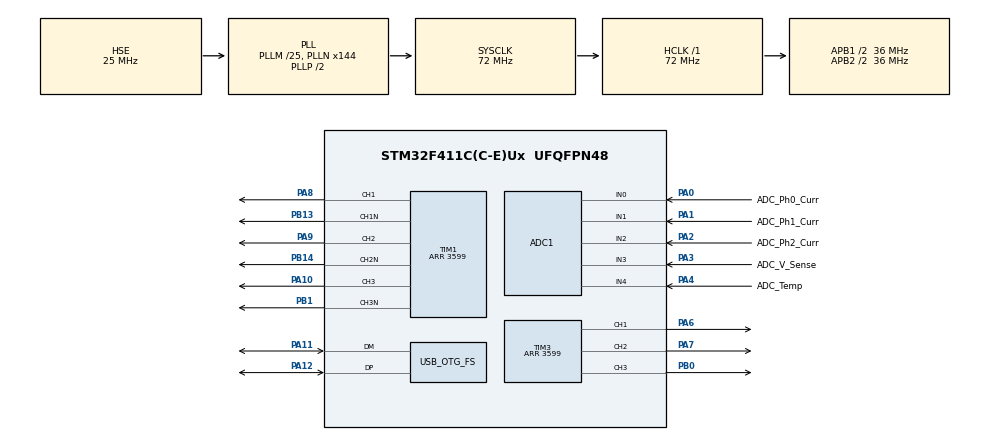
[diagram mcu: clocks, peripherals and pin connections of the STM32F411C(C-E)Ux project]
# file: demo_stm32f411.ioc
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ADC1.Channel-0\#ChannelRegularConversion=ADC_CHANNEL_0
ADC1.NbrOfConversionFlag=1
ADC1.Rank-0\#ChannelRegularConversion=1
ADC1.SamplingTime-0\#ChannelRegularConversion=ADC_SAMPLETIME_3CYCLES
ADC1.master=1
FREERTOS.Queues01=usbQueue,16,uint16_t,0,Dynamic,NULL,NULL
FREERTOS.Tasks01=defaultTask,24,1024,StartDefaultTask,Default,NULL,Dynamic,NULL,NULL;telemTask,8,1024,TelemThread,As external,NULL,Dynamic,NULL,NULL;usbTask,8,1024,UsbThread,As external,NULL,Dynamic,NULL,NULL
Mcu.Family=STM32F4
Mcu.Name=STM32F411C(C-E)Ux
Mcu.Package=UFQFPN48
NVIC.OTG_FS_IRQn=true\:5\:0\:false\:false\:true\:true\:false\:true\:true
NVIC.PriorityGroup=NVIC_PRIORITYGROUP_4
NVIC.TIM5_IRQn=true\:15\:0\:false\:false\:true\:false\:false\:true\:true
NVIC.TimeBase=TIM5_IRQn
NVIC.TimeBaseIP=TIM5
PA0-WKUP.GPIO_Label=ADC_Ph0_Curr
PA0-WKUP.Signal=ADCx_IN0
PA1.GPIO_Label=ADC_Ph1_Curr
PA1.Signal=ADCx_IN1
PA10.Signal=S_TIM1_CH3
PA11.Mode=Device_Only
PA11.Signal=USB_OTG_FS_DM
PA12.Mode=Device_Only
PA12.Signal=USB_OTG_FS_DP
PA13.Mode=Serial_Wire
PA13.Signal=SYS_JTMS-SWDIO
PA14.Mode=Serial_Wire
PA14.Signal=SYS_JTCK-SWCLK
PA2.GPIO_Label=ADC_Ph2_Curr
PA2.Signal=ADCx_IN2
PA3.GPIO_Label=ADC_V_Sense
PA3.Signal=ADCx_IN3
PA4.GPIO_Label=ADC_Temp
PA4.Signal=ADCx_IN4
PA6.Signal=S_TIM3_CH1
PA7.Signal=S_TIM3_CH2
PA8.Signal=S_TIM1_CH1
PA9.Signal=S_TIM1_CH2
PB0.Signal=S_TIM3_CH3
PB1.Mode=PWM Generation3 CH3 CH3N
PB1.Signal=TIM1_CH3N
PB13.Mode=PWM Generation1 CH1 CH1N
PB13.Signal=TIM1_CH1N
PB14.Mode=PWM Generation2 CH2 CH2N
PB14.Signal=TIM1_CH2N
PH0\ -\ OSC_IN.Mode=HSE-External-Oscillator
PH0\ -\ OSC_IN.Signal=RCC_OSC_IN
PH1\ -\ OSC_OUT.Mode=HSE-External-Oscillator
PH1\ -\ OSC_OUT.Signal=RCC_OSC_OUT
ProjectManager.HeapSize=0x200
ProjectManager.StackSize=0x400
ProjectManager.TargetToolchain=CMake
RCC.48MHZClocksFreq_Value=48000000
RCC.AHBFreq_Value=72000000
RCC.APB1CLKDivider=RCC_HCLK_DIV2
RCC.APB1Freq_Value=36000000
RCC.APB1TimFreq_Value=72000000
RCC.APB2CLKDivider=RCC_HCLK_DIV2
RCC.APB2Freq_Value=36000000
RCC.APB2TimFreq_Value=72000000
RCC.CortexFreq_Value=72000000
RCC.HCLKFreq_Value=72000000
RCC.HSE_VALUE=25000000
RCC.HSI_VALUE=16000000
RCC.LSE_VALUE=32768
RCC.PLLM=25
RCC.PLLN=144
RCC.PLLQ=3
RCC.SYSCLKFreq_VALUE=72000000
RCC.SYSCLKSource=RCC_SYSCLKSOURCE_PLLCLK
RCC.VCOOutputFreq_Value=144000000
SH.ADCx_IN0.0=ADC1_IN0,IN0
SH.ADCx_IN1.0=ADC1_IN1,IN1
SH.ADCx_IN2.0=ADC1_IN2,IN2
SH.ADCx_IN3.0=ADC1_IN3,IN3
SH.ADCx_IN4.0=ADC1_IN4,IN4
SH.S_TIM1_CH1.0=TIM1_CH1,PWM Generation1 CH1 CH1N
SH.S_TIM1_CH2.0=TIM1_CH2,PWM Generation2 CH2 CH2N
SH.S_TIM1_CH3.0=TIM1_CH3,PWM Generation3 CH3 CH3N
SH.S_TIM3_CH1.0=TIM3_CH1,PWM Generation1 CH1
SH.S_TIM3_CH2.0=TIM3_CH2,PWM Generation2 CH2
SH.S_TIM3_CH3.0=TIM3_CH3,PWM Generation3 CH3
TIM1.Channel-PWM\ Generation1\ CH1\ CH1N=TIM_CHANNEL_1
TIM1.Channel-PWM\ Generation2\ CH2\ CH2N=TIM_CHANNEL_2
TIM1.Channel-PWM\ Generation3\ CH3\ CH3N=TIM_CHANNEL_3
TIM1.Period=3599
TIM3.Channel-PWM\ Generation1\ CH1=TIM_CHANNEL_1
TIM3.Channel-PWM\ Generation2\ CH2=TIM_CHANNEL_2
TIM3.Channel-PWM\ Generation3\ CH3=TIM_CHANNEL_3
TIM3.OCMode_PWM-PWM\ Generation1\ CH1=TIM_OCMODE_PWM1
TIM3.Period=3599
USB_DEVICE.CLASS_NAME_FS=CDC
USB_DEVICE.VirtualMode=Cdc
USB_DEVICE.VirtualModeFS=Cdc_FS
USB_OTG_FS.VirtualMode=Device_Only
VP_FREERTOS_VS_CMSIS_V2.Mode=CMSIS_V2
VP_SYS_VS_tim5.Mode=TIM5
VP_USB_DEVICE_VS_USB_DEVICE_CDC_FS.Mode=CDC_FS
board=custom

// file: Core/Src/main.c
/* USER CODE BEGIN Header */
/**
  ******************************************************************************
  * @file           : main.c
  * @brief          : Main program body
  ******************************************************************************
  * @attention
  *
  * Copyright (c) 2026 STMicroelectronics.
  * All rights reserved.
  *
  * This software is licensed under terms that can be found in the LICENSE file
  * in the root directory of this software component.
  * If no LICENSE file comes with this software, it is provided AS-IS.
  *
  ******************************************************************************
  */
/* USER CODE END Header */
#include "main.h"
#include "cmsis_os.h"
#include "usb_device.h"

/* USER CODE BEGIN Includes */
#include "bldc.h"
#include "usbd_cdc.h"
#include "usbd_cdc_if.h"

/* USER CODE END Includes */

ADC_HandleTypeDef hadc1;

TIM_HandleTypeDef htim1;
TIM_HandleTypeDef htim3;

/* Definitions for defaultTask */
osThreadId_t defaultTaskHandle;
const osThreadAttr_t defaultTask_attributes = {
  .name = "defaultTask",
  .stack_size = 1024 * 4,
  .priority = (osPriority_t) osPriorityNormal,
};
/* Definitions for telemTask */
osThreadId_t telemTaskHandle;
const osThreadAttr_t telemTask_attributes = {
  .name = "telemTask",
  .stack_size = 1024 * 4,
  .priority = (osPriority_t) osPriorityLow,
};
/* Definitions for usbTask */
osThreadId_t usbTaskHandle;
const osThreadAttr_t usbTask_attributes = {
  .name = "usbTask",
  .stack_size = 1024 * 4,
  .priority = (osPriority_t) osPriorityLow,
};
/* Definitions for usbQueue */
osMessageQueueId_t usbQueueHandle;
const osMessageQueueAttr_t usbQueue_attributes = {
  .name = "usbQueue"
};
/* USER CODE BEGIN PV */

BLDC_Handle_t motor = {
	.htim = &htim3,
	.chA = PHASE_1_CH,
	.chB = PHASE_2_CH,
	.chC = PHASE_3_CH
};
/* USER CODE END PV */

void SystemClock_Config(void);
static void MX_GPIO_Init(void);
static void MX_TIM3_Init(void);
static void MX_TIM1_Init(void);
static void MX_ADC1_Init(void);
void StartDefaultTask(void *argument);
extern void TelemThread(void *argument);
extern void UsbThread(void *argument);

int main(void)
{

  /* MCU Configuration--------------------------------------------------------*/

  /* Reset of all peripherals, Initializes the Flash interface and the Systick. */
  HAL_Init();

  /* Configure the system clock */
  SystemClock_Config();

  /* Initialize all configured peripherals */
  MX_GPIO_Init();
  MX_TIM3_Init();
  MX_TIM1_Init();
  MX_ADC1_Init();
  /* USER CODE BEGIN 2 */
	bldc_comm_init(&motor);
  bldc_telem_init();
  bldc_dronecan_init();
  /* USER CODE END 2 */

  /* Init scheduler */
  osKernelInitialize();

  /* Create the queue(s) */
  /* creation of usbQueue */
  usbQueueHandle = osMessageQueueNew (16, sizeof(uint16_t), &usbQueue_attributes);

  /* Create the thread(s) */
  /* creation of defaultTask */
  defaultTaskHandle = osThreadNew(StartDefaultTask, NULL, &defaultTask_attributes);

  /* creation of telemTask */
  telemTaskHandle = osThreadNew(TelemThread, NULL, &telemTask_attributes);

  /* creation of usbTask */
  usbTaskHandle = osThreadNew(UsbThread, NULL, &usbTask_attributes);

  /* Start scheduler */
  osKernelStart();

  /* We should never get here as control is now taken by the scheduler */

  /* Infinite loop */
  while (1)
  {

  }
}

void SystemClock_Config(void)
{
  RCC_OscInitTypeDef RCC_OscInitStruct = {0};
  RCC_ClkInitTypeDef RCC_ClkInitStruct = {0};

  /** Configure the main internal regulator output voltage
  */
  __HAL_RCC_PWR_CLK_ENABLE();
  __HAL_PWR_VOLTAGESCALING_CONFIG(PWR_REGULATOR_VOLTAGE_SCALE1);

  /** Initializes the RCC Oscillators according to the specified parameters
  * in the RCC_OscInitTypeDef structure.
  */
  RCC_OscInitStruct.OscillatorType = RCC_OSCILLATORTYPE_HSE;
  RCC_OscInitStruct.HSEState = RCC_HSE_ON;
  RCC_OscInitStruct.PLL.PLLState = RCC_PLL_ON;
  RCC_OscInitStruct.PLL.PLLSource = RCC_PLLSOURCE_HSE;
  RCC_OscInitStruct.PLL.PLLM = 25;
  RCC_OscInitStruct.PLL.PLLN = 144;
  RCC_OscInitStruct.PLL.PLLP = RCC_PLLP_DIV2;
  RCC_OscInitStruct.PLL.PLLQ = 3;
  if (HAL_RCC_OscConfig(&RCC_OscInitStruct) != HAL_OK)
  {
    Error_Handler();
  }

  /** Initializes the CPU, AHB and APB buses clocks
  */
  RCC_ClkInitStruct.ClockType = RCC_CLOCKTYPE_HCLK|RCC_CLOCKTYPE_SYSCLK
                              |RCC_CLOCKTYPE_PCLK1|RCC_CLOCKTYPE_PCLK2;
  RCC_ClkInitStruct.SYSCLKSource = RCC_SYSCLKSOURCE_PLLCLK;
  RCC_ClkInitStruct.AHBCLKDivider = RCC_SYSCLK_DIV1;
  RCC_ClkInitStruct.APB1CLKDivider = RCC_HCLK_DIV2;
  RCC_ClkInitStruct.APB2CLKDivider = RCC_HCLK_DIV2;

  if (HAL_RCC_ClockConfig(&RCC_ClkInitStruct, FLASH_LATENCY_2) != HAL_OK)
  {
    Error_Handler();
  }
}

static void MX_ADC1_Init(void)
{

  ADC_ChannelConfTypeDef sConfig = {0};

  /** Configure the global features of the ADC (Clock, Resolution, Data Alignment and number of conversion)
  */
  hadc1.Instance = ADC1;
  hadc1.Init.ClockPrescaler = ADC_CLOCK_SYNC_PCLK_DIV2;
  hadc1.Init.Resolution = ADC_RESOLUTION_12B;
  hadc1.Init.ScanConvMode = DISABLE;
  hadc1.Init.ContinuousConvMode = DISABLE;
  hadc1.Init.DiscontinuousConvMode = DISABLE;
  hadc1.Init.ExternalTrigConvEdge = ADC_EXTERNALTRIGCONVEDGE_NONE;
  hadc1.Init.ExternalTrigConv = ADC_SOFTWARE_START;
  hadc1.Init.DataAlign = ADC_DATAALIGN_RIGHT;
  hadc1.Init.NbrOfConversion = 1;
  hadc1.Init.DMAContinuousRequests = DISABLE;
  hadc1.Init.EOCSelection = ADC_EOC_SINGLE_CONV;
  if (HAL_ADC_Init(&hadc1) != HAL_OK)
  {
    Error_Handler();
  }

  /** Configure for the selected ADC regular channel its corresponding rank in the sequencer and its sample time.
  */
  sConfig.Channel = ADC_CHANNEL_0;
  sConfig.Rank = 1;
  sConfig.SamplingTime = ADC_SAMPLETIME_3CYCLES;
  if (HAL_ADC_ConfigChannel(&hadc1, &sConfig) != HAL_OK)
  {
    Error_Handler();
  }

}

static void MX_TIM1_Init(void)
{

  TIM_MasterConfigTypeDef sMasterConfig = {0};
  TIM_OC_InitTypeDef sConfigOC = {0};
  TIM_BreakDeadTimeConfigTypeDef sBreakDeadTimeConfig = {0};

  htim1.Instance = TIM1;
  htim1.Init.Prescaler = 0;
  htim1.Init.CounterMode = TIM_COUNTERMODE_UP;
  htim1.Init.Period = 3599;
  htim1.Init.ClockDivision = TIM_CLOCKDIVISION_DIV1;
  htim1.Init.RepetitionCounter = 0;
  htim1.Init.AutoReloadPreload = TIM_AUTORELOAD_PRELOAD_DISABLE;
  if (HAL_TIM_PWM_Init(&htim1) != HAL_OK)
  {
    Error_Handler();
  }
  sMasterConfig.MasterOutputTrigger = TIM_TRGO_RESET;
  sMasterConfig.MasterSlaveMode = TIM_MASTERSLAVEMODE_DISABLE;
  if (HAL_TIMEx_MasterConfigSynchronization(&htim1, &sMasterConfig) != HAL_OK)
  {
    Error_Handler();
  }
  sConfigOC.OCMode = TIM_OCMODE_PWM1;
  sConfigOC.Pulse = 0;
  sConfigOC.OCPolarity = TIM_OCPOLARITY_HIGH;
  sConfigOC.OCNPolarity = TIM_OCNPOLARITY_HIGH;
  sConfigOC.OCFastMode = TIM_OCFAST_DISABLE;
  sConfigOC.OCIdleState = TIM_OCIDLESTATE_RESET;
  sConfigOC.OCNIdleState = TIM_OCNIDLESTATE_RESET;
  if (HAL_TIM_PWM_ConfigChannel(&htim1, &sConfigOC, TIM_CHANNEL_1) != HAL_OK)
  {
    Error_Handler();
  }
  if (HAL_TIM_PWM_ConfigChannel(&htim1, &sConfigOC, TIM_CHANNEL_2) != HAL_OK)
  {
    Error_Handler();
  }
  if (HAL_TIM_PWM_ConfigChannel(&htim1, &sConfigOC, TIM_CHANNEL_3) != HAL_OK)
  {
    Error_Handler();
  }
  sBreakDeadTimeConfig.OffStateRunMode = TIM_OSSR_DISABLE;
  sBreakDeadTimeConfig.OffStateIDLEMode = TIM_OSSI_DISABLE;
  sBreakDeadTimeConfig.LockLevel = TIM_LOCKLEVEL_OFF;
  sBreakDeadTimeConfig.DeadTime = 0;
  sBreakDeadTimeConfig.BreakState = TIM_BREAK_DISABLE;
  sBreakDeadTimeConfig.BreakPolarity = TIM_BREAKPOLARITY_HIGH;
  sBreakDeadTimeConfig.AutomaticOutput = TIM_AUTOMATICOUTPUT_DISABLE;
  if (HAL_TIMEx_ConfigBreakDeadTime(&htim1, &sBreakDeadTimeConfig) != HAL_OK)
  {
    Error_Handler();
  }
  HAL_TIM_MspPostInit(&htim1);

}

static void MX_TIM3_Init(void)
{

  TIM_MasterConfigTypeDef sMasterConfig = {0};
  TIM_OC_InitTypeDef sConfigOC = {0};

  htim3.Instance = TIM3;
  htim3.Init.Prescaler = 0;
  htim3.Init.CounterMode = TIM_COUNTERMODE_UP;
  htim3.Init.Period = 3599;
  htim3.Init.ClockDivision = TIM_CLOCKDIVISION_DIV1;
  htim3.Init.AutoReloadPreload = TIM_AUTORELOAD_PRELOAD_DISABLE;
  if (HAL_TIM_PWM_Init(&htim3) != HAL_OK)
  {
    Error_Handler();
  }
  sMasterConfig.MasterOutputTrigger = TIM_TRGO_RESET;
  sMasterConfig.MasterSlaveMode = TIM_MASTERSLAVEMODE_DISABLE;
  if (HAL_TIMEx_MasterConfigSynchronization(&htim3, &sMasterConfig) != HAL_OK)
  {
    Error_Handler();
  }
  sConfigOC.OCMode = TIM_OCMODE_PWM1;
  sConfigOC.Pulse = 0;
  sConfigOC.OCPolarity = TIM_OCPOLARITY_HIGH;
  sConfigOC.OCFastMode = TIM_OCFAST_DISABLE;
  if (HAL_TIM_PWM_ConfigChannel(&htim3, &sConfigOC, TIM_CHANNEL_1) != HAL_OK)
  {
    Error_Handler();
  }
  if (HAL_TIM_PWM_ConfigChannel(&htim3, &sConfigOC, TIM_CHANNEL_2) != HAL_OK)
  {
    Error_Handler();
  }
  if (HAL_TIM_PWM_ConfigChannel(&htim3, &sConfigOC, TIM_CHANNEL_3) != HAL_OK)
  {
    Error_Handler();
  }
  HAL_TIM_MspPostInit(&htim3);

}

static void MX_GPIO_Init(void)
{

  /* GPIO Ports Clock Enable */
  __HAL_RCC_GPIOH_CLK_ENABLE();
  __HAL_RCC_GPIOA_CLK_ENABLE();
  __HAL_RCC_GPIOB_CLK_ENABLE();

}

void StartDefaultTask(void *argument)
{
  /* init code for USB_DEVICE */
  MX_USB_DEVICE_Init();
  /* USER CODE BEGIN 5 */
  /* Infinite loop */
  for(;;)
  {
    osDelay(10);
  }
  /* USER CODE END 5 */
}

void HAL_TIM_PeriodElapsedCallback(TIM_HandleTypeDef *htim)
{
  if (htim->Instance == TIM5)
  {
    HAL_IncTick();
  }
}

void Error_Handler(void)
{
  __disable_irq();
  while (1)
  {
  }
}
